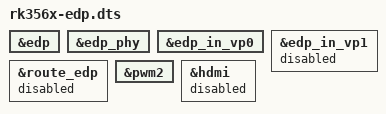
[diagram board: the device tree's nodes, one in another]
/dts-v1/;
/plugin/;

#include <dt-bindings/gpio/gpio.h>
#include <dt-bindings/pinctrl/rockchip.h>
#include <dt-bindings/display/rockchip_vop.h>

/ {
	fragment@0 {
		target = <&edp>;

		__overlay__ {
			status = "okay";
		};
	};

	fragment@1 {
		target = <&edp_phy>;

		__overlay__ {
			status = "okay";
		};
	};

	fragment@2 {
		target = <&edp_in_vp0>;

		__overlay__ {
			status = "okay";
		};
	};

	fragment@3 {
		target = <&edp_in_vp1>;

		__overlay__ {
			status = "disabled";
		};
	};

	fragment@4 {
		target = <&route_edp>;

		__overlay__ {
			status = "disabled";
		};
	};

	fragment@5 {
		target = <&pwm2>;

		__overlay__ {
			status = "okay";
		};
	};

	fragment@6 {
		target = <&hdmi>;
		__overlay__ {
			status = "disabled";
		};
	};
};
